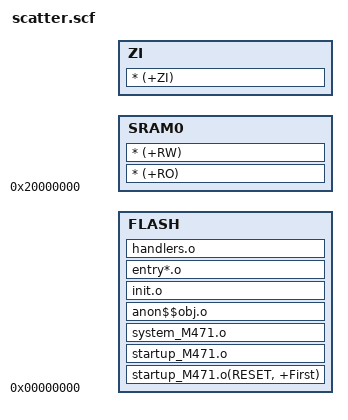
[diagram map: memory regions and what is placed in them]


FLASH 0x00000000 0x00003000
{
    FLASH +0
    {
         startup_M471.o(RESET, +First)
         startup_M471.o
         system_M471.o
         anon$$obj.o
         init.o
         entry*.o
         handlers.o
    }

    SRAM0 0x20000000
    {
        * (+RO)	
        * (+RW)
    }

    ZI +0
    {
        * (+ZI)
    }
}
